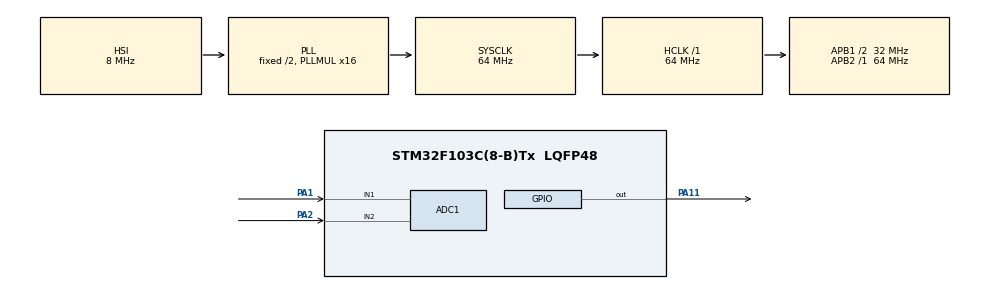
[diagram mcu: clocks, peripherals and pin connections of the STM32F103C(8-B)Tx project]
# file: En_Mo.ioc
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ADC1.Channel-0\#ChannelRegularConversion=ADC_CHANNEL_1
ADC1.Channel-1\#ChannelRegularConversion=ADC_CHANNEL_2
ADC1.ContinuousConvMode=ENABLE
ADC1.NbrOfConversion=2
ADC1.NbrOfConversionFlag=1
ADC1.Rank-0\#ChannelRegularConversion=1
ADC1.Rank-1\#ChannelRegularConversion=2
ADC1.SamplingTime-0\#ChannelRegularConversion=ADC_SAMPLETIME_1CYCLE_5
ADC1.SamplingTime-1\#ChannelRegularConversion=ADC_SAMPLETIME_1CYCLE_5
ADC1.master=1
Mcu.Family=STM32F1
Mcu.Name=STM32F103C(8-B)Tx
Mcu.Package=LQFP48
NVIC.PriorityGroup=NVIC_PRIORITYGROUP_4
NVIC.RTC_IRQn=true\:1\:0\:true\:false\:true\:true\:true\:true
NVIC.TIM1_UP_IRQn=true\:1\:0\:true\:false\:true\:true\:true\:true
NVIC.TIM2_IRQn=true\:1\:0\:true\:false\:true\:true\:true\:true
NVIC.TIM3_IRQn=true\:1\:0\:true\:false\:true\:true\:true\:true
PA1.Signal=ADCx_IN1
PA11.Signal=GPIO_Output
PA13.Mode=Serial_Wire
PA13.Signal=SYS_JTMS-SWDIO
PA14.Mode=Serial_Wire
PA14.Signal=SYS_JTCK-SWCLK
PA2.Signal=ADCx_IN2
ProjectManager.HeapSize=0x200
ProjectManager.StackSize=0x400
ProjectManager.TargetToolchain=STM32CubeIDE
RCC.AHBFreq_Value=64000000
RCC.APB1CLKDivider=RCC_HCLK_DIV2
RCC.APB1Freq_Value=32000000
RCC.APB1TimFreq_Value=64000000
RCC.APB2Freq_Value=64000000
RCC.APB2TimFreq_Value=64000000
RCC.HCLKFreq_Value=64000000
RCC.PLLMUL=RCC_PLL_MUL16
RCC.SYSCLKFreq_VALUE=64000000
RCC.SYSCLKSource=RCC_SYSCLKSOURCE_PLLCLK
RCC.USBFreq_Value=64000000
RTC.OutPut=RTC_OUTPUTSOURCE_SECOND
SH.ADCx_IN1.0=ADC1_IN1,IN1
SH.ADCx_IN2.0=ADC1_IN2,IN2
TIM1.Period=1000
TIM1.Prescaler=63
TIM2.Period=1000
TIM2.Prescaler=63
TIM3.Period=1000
TIM3.Prescaler=63999
VP_RTC_VS_RTC_Activate.Mode=RTC_Enabled
VP_TIM1_VS_ClockSourceINT.Mode=Internal
VP_TIM2_VS_ClockSourceINT.Mode=Internal
VP_TIM3_VS_ClockSourceINT.Mode=Internal
board=custom

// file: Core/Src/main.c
/* USER CODE BEGIN Header */
/**
  ******************************************************************************
  * @file           : main.c
  * @brief          : Main program body
  ******************************************************************************
  * @attention
  *
  * Copyright (c) 2024 STMicroelectronics.
  * All rights reserved.
  *
  * This software is licensed under terms that can be found in the LICENSE file
  * in the root directory of this software component.
  * If no LICENSE file comes with this software, it is provided AS-IS.
  *
  ******************************************************************************
  */
/* USER CODE END Header */
#include "main.h"

/* USER CODE BEGIN Includes */
#include "mainApp.h"
/* USER CODE END Includes */

ADC_HandleTypeDef hadc1;

RTC_HandleTypeDef hrtc;

TIM_HandleTypeDef htim1;
TIM_HandleTypeDef htim2;
TIM_HandleTypeDef htim3;

void SystemClock_Config(void);
static void MX_GPIO_Init(void);
static void MX_TIM1_Init(void);
static void MX_TIM2_Init(void);
static void MX_TIM3_Init(void);
static void MX_RTC_Init(void);
static void MX_ADC1_Init(void);

/* USER CODE BEGIN 0 */

uint8_t rx_data;
uint8_t tx_data[20]="STM32 Hello Man!!\r\n";

/* USER CODE END 0 */

int main(void)
{

  /* MCU Configuration--------------------------------------------------------*/

  /* Reset of all peripherals, Initializes the Flash interface and the Systick. */
  HAL_Init();

  /* Configure the system clock */
  SystemClock_Config();

  /* Initialize all configured peripherals */
  MX_GPIO_Init();
  MX_TIM1_Init();
  MX_TIM2_Init();
  MX_TIM3_Init();
  MX_RTC_Init();
  MX_ADC1_Init();

  /* Infinite loop */
  while (1)
  {

    /* USER CODE BEGIN 3 */
//	  HAL_UART_Transmit(&huart1, &data, 1, 100);
	  mainApp();
	  HAL_Delay(200);
  }
  /* USER CODE END 3 */
}

void SystemClock_Config(void)
{
  RCC_OscInitTypeDef RCC_OscInitStruct = {0};
  RCC_ClkInitTypeDef RCC_ClkInitStruct = {0};
  RCC_PeriphCLKInitTypeDef PeriphClkInit = {0};

  /** Initializes the RCC Oscillators according to the specified parameters
  * in the RCC_OscInitTypeDef structure.
  */
  RCC_OscInitStruct.OscillatorType = RCC_OSCILLATORTYPE_HSI|RCC_OSCILLATORTYPE_LSI;
  RCC_OscInitStruct.HSIState = RCC_HSI_ON;
  RCC_OscInitStruct.HSICalibrationValue = RCC_HSICALIBRATION_DEFAULT;
  RCC_OscInitStruct.LSIState = RCC_LSI_ON;
  RCC_OscInitStruct.PLL.PLLState = RCC_PLL_ON;
  RCC_OscInitStruct.PLL.PLLSource = RCC_PLLSOURCE_HSI_DIV2;
  RCC_OscInitStruct.PLL.PLLMUL = RCC_PLL_MUL16;
  if (HAL_RCC_OscConfig(&RCC_OscInitStruct) != HAL_OK)
  {
    Error_Handler();
  }

  /** Initializes the CPU, AHB and APB buses clocks
  */
  RCC_ClkInitStruct.ClockType = RCC_CLOCKTYPE_HCLK|RCC_CLOCKTYPE_SYSCLK
                              |RCC_CLOCKTYPE_PCLK1|RCC_CLOCKTYPE_PCLK2;
  RCC_ClkInitStruct.SYSCLKSource = RCC_SYSCLKSOURCE_PLLCLK;
  RCC_ClkInitStruct.AHBCLKDivider = RCC_SYSCLK_DIV1;
  RCC_ClkInitStruct.APB1CLKDivider = RCC_HCLK_DIV2;
  RCC_ClkInitStruct.APB2CLKDivider = RCC_HCLK_DIV1;

  if (HAL_RCC_ClockConfig(&RCC_ClkInitStruct, FLASH_LATENCY_2) != HAL_OK)
  {
    Error_Handler();
  }
  PeriphClkInit.PeriphClockSelection = RCC_PERIPHCLK_RTC|RCC_PERIPHCLK_ADC;
  PeriphClkInit.RTCClockSelection = RCC_RTCCLKSOURCE_LSI;
  PeriphClkInit.AdcClockSelection = RCC_ADCPCLK2_DIV2;
  if (HAL_RCCEx_PeriphCLKConfig(&PeriphClkInit) != HAL_OK)
  {
    Error_Handler();
  }
}

static void MX_ADC1_Init(void)
{

  ADC_ChannelConfTypeDef sConfig = {0};

  /** Common config
  */
  hadc1.Instance = ADC1;
  hadc1.Init.ScanConvMode = ADC_SCAN_ENABLE;
  hadc1.Init.ContinuousConvMode = ENABLE;
  hadc1.Init.DiscontinuousConvMode = DISABLE;
  hadc1.Init.ExternalTrigConv = ADC_SOFTWARE_START;
  hadc1.Init.DataAlign = ADC_DATAALIGN_RIGHT;
  hadc1.Init.NbrOfConversion = 1;
  if (HAL_ADC_Init(&hadc1) != HAL_OK)
  {
    Error_Handler();
  }

  /** Configure Regular Channel
  */
//  sConfig.Channel = ADC_CHANNEL_1;
//  sConfig.Rank = ADC_REGULAR_RANK_1;
//  sConfig.SamplingTime = ADC_SAMPLETIME_1CYCLE_5;
//  if (HAL_ADC_ConfigChannel(&hadc1, &sConfig) != HAL_OK)
//  {
//    Error_Handler();
//  }

  /** Configure Regular Channel
  */
//  sConfig.Channel = ADC_CHANNEL_2;
//  sConfig.Rank = ADC_REGULAR_RANK_2;
//  if (HAL_ADC_ConfigChannel(&hadc1, &sConfig) != HAL_OK)
//  {
//    Error_Handler();
//  }

}

static void MX_RTC_Init(void)
{

  /** Initialize RTC Only
  */
  hrtc.Instance = RTC;
  hrtc.Init.AsynchPrediv = RTC_AUTO_1_SECOND;
  hrtc.Init.OutPut = RTC_OUTPUTSOURCE_SECOND;
  if (HAL_RTC_Init(&hrtc) != HAL_OK)
  {
    Error_Handler();
  }

}

static void MX_TIM1_Init(void)
{

  TIM_ClockConfigTypeDef sClockSourceConfig = {0};
  TIM_MasterConfigTypeDef sMasterConfig = {0};

  htim1.Instance = TIM1;
  htim1.Init.Prescaler = 63;
  htim1.Init.CounterMode = TIM_COUNTERMODE_UP;
  htim1.Init.Period = 1000;
  htim1.Init.ClockDivision = TIM_CLOCKDIVISION_DIV1;
  htim1.Init.RepetitionCounter = 0;
  htim1.Init.AutoReloadPreload = TIM_AUTORELOAD_PRELOAD_DISABLE;
  if (HAL_TIM_Base_Init(&htim1) != HAL_OK)
  {
    Error_Handler();
  }
  sClockSourceConfig.ClockSource = TIM_CLOCKSOURCE_INTERNAL;
  if (HAL_TIM_ConfigClockSource(&htim1, &sClockSourceConfig) != HAL_OK)
  {
    Error_Handler();
  }
  sMasterConfig.MasterOutputTrigger = TIM_TRGO_RESET;
  sMasterConfig.MasterSlaveMode = TIM_MASTERSLAVEMODE_DISABLE;
  if (HAL_TIMEx_MasterConfigSynchronization(&htim1, &sMasterConfig) != HAL_OK)
  {
    Error_Handler();
  }

}

static void MX_TIM2_Init(void)
{

  TIM_ClockConfigTypeDef sClockSourceConfig = {0};
  TIM_MasterConfigTypeDef sMasterConfig = {0};

  htim2.Instance = TIM2;
  htim2.Init.Prescaler = 63;
  htim2.Init.CounterMode = TIM_COUNTERMODE_UP;
  htim2.Init.Period = 1000;
  htim2.Init.ClockDivision = TIM_CLOCKDIVISION_DIV1;
  htim2.Init.AutoReloadPreload = TIM_AUTORELOAD_PRELOAD_DISABLE;
  if (HAL_TIM_Base_Init(&htim2) != HAL_OK)
  {
    Error_Handler();
  }
  sClockSourceConfig.ClockSource = TIM_CLOCKSOURCE_INTERNAL;
  if (HAL_TIM_ConfigClockSource(&htim2, &sClockSourceConfig) != HAL_OK)
  {
    Error_Handler();
  }
  sMasterConfig.MasterOutputTrigger = TIM_TRGO_RESET;
  sMasterConfig.MasterSlaveMode = TIM_MASTERSLAVEMODE_DISABLE;
  if (HAL_TIMEx_MasterConfigSynchronization(&htim2, &sMasterConfig) != HAL_OK)
  {
    Error_Handler();
  }

}

static void MX_TIM3_Init(void)
{

  TIM_ClockConfigTypeDef sClockSourceConfig = {0};
  TIM_MasterConfigTypeDef sMasterConfig = {0};

  htim3.Instance = TIM3;
  htim3.Init.Prescaler = 63999;
  htim3.Init.CounterMode = TIM_COUNTERMODE_UP;
  htim3.Init.Period = 1000;
  htim3.Init.ClockDivision = TIM_CLOCKDIVISION_DIV1;
  htim3.Init.AutoReloadPreload = TIM_AUTORELOAD_PRELOAD_DISABLE;
  if (HAL_TIM_Base_Init(&htim3) != HAL_OK)
  {
    Error_Handler();
  }
  sClockSourceConfig.ClockSource = TIM_CLOCKSOURCE_INTERNAL;
  if (HAL_TIM_ConfigClockSource(&htim3, &sClockSourceConfig) != HAL_OK)
  {
    Error_Handler();
  }
  sMasterConfig.MasterOutputTrigger = TIM_TRGO_RESET;
  sMasterConfig.MasterSlaveMode = TIM_MASTERSLAVEMODE_DISABLE;
  if (HAL_TIMEx_MasterConfigSynchronization(&htim3, &sMasterConfig) != HAL_OK)
  {
    Error_Handler();
  }

}

static void MX_GPIO_Init(void)
{
  GPIO_InitTypeDef GPIO_InitStruct = {0};

  /* GPIO Ports Clock Enable */
  __HAL_RCC_GPIOA_CLK_ENABLE();

  /*Configure GPIO pin Output Level */
  HAL_GPIO_WritePin(GPIOA, GPIO_PIN_11, GPIO_PIN_RESET);

  /*Configure GPIO pin : PA11 */
  GPIO_InitStruct.Pin = GPIO_PIN_11;
  GPIO_InitStruct.Mode = GPIO_MODE_OUTPUT_PP;
  GPIO_InitStruct.Pull = GPIO_NOPULL;
  GPIO_InitStruct.Speed = GPIO_SPEED_FREQ_LOW;
  HAL_GPIO_Init(GPIOA, &GPIO_InitStruct);

}

void Error_Handler(void)
{
  __disable_irq();
  while (1)
  {
  }
}
